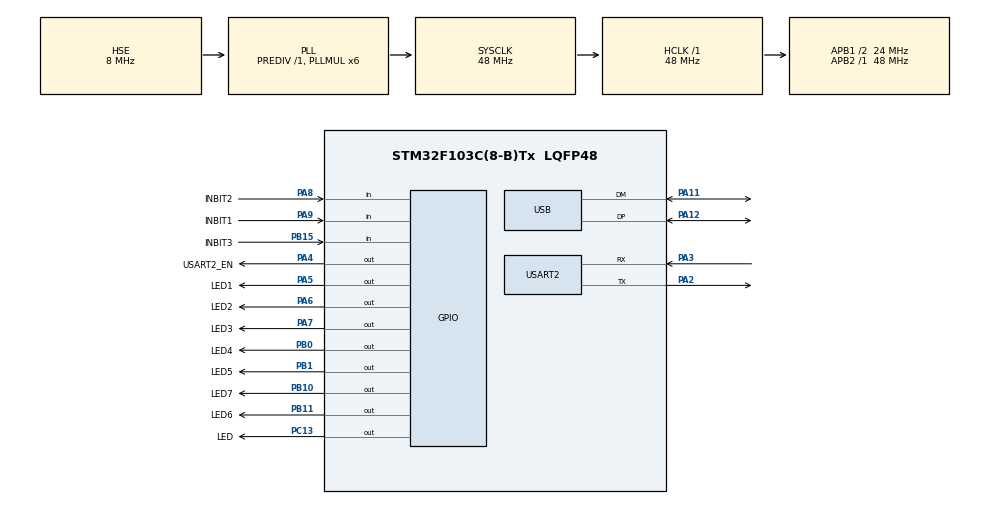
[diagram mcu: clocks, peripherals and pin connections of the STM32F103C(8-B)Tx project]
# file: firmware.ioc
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Mcu.Family=STM32F1
Mcu.Name=STM32F103C(8-B)Tx
Mcu.Package=LQFP48
NVIC.PriorityGroup=NVIC_PRIORITYGROUP_4
NVIC.USB_LP_CAN1_RX0_IRQn=true\:0\:0\:false\:false\:true\:false\:true\:true
PA11.Mode=Device
PA11.Signal=USB_DM
PA12.Mode=Device
PA12.Signal=USB_DP
PA13.Mode=Serial_Wire
PA13.Signal=SYS_JTMS-SWDIO
PA14.Mode=Serial_Wire
PA14.Signal=SYS_JTCK-SWCLK
PA2.Mode=Asynchronous
PA2.Signal=USART2_TX
PA3.Mode=Asynchronous
PA3.Signal=USART2_RX
PA4.GPIO_Label=USART2_EN
PA4.Signal=GPIO_Output
PA5.GPIO_Label=LED1
PA5.Signal=GPIO_Output
PA6.GPIO_Label=LED2
PA6.Signal=GPIO_Output
PA7.GPIO_Label=LED3
PA7.Signal=GPIO_Output
PA8.GPIO_Label=INBIT2
PA8.GPIO_PuPd=GPIO_PULLUP
PA8.Signal=GPIO_Input
PA9.GPIO_Label=INBIT1
PA9.GPIO_PuPd=GPIO_PULLUP
PA9.Signal=GPIO_Input
PB0.GPIO_Label=LED4
PB0.Signal=GPIO_Output
PB1.GPIO_Label=LED5
PB1.Signal=GPIO_Output
PB10.GPIO_Label=LED7
PB10.Signal=GPIO_Output
PB11.GPIO_Label=LED6
PB11.Signal=GPIO_Output
PB15.GPIO_Label=INBIT3
PB15.GPIO_PuPd=GPIO_PULLUP
PB15.Signal=GPIO_Input
PC13-TAMPER-RTC.GPIO_Label=LED
PC13-TAMPER-RTC.Signal=GPIO_Output
PD0-OSC_IN.Mode=HSE-External-Oscillator
PD0-OSC_IN.Signal=RCC_OSC_IN
PD1-OSC_OUT.Mode=HSE-External-Oscillator
PD1-OSC_OUT.Signal=RCC_OSC_OUT
ProjectManager.HeapSize=0x200
ProjectManager.StackSize=0x400
ProjectManager.TargetToolchain=STM32CubeIDE
RCC.AHBFreq_Value=48000000
RCC.APB1CLKDivider=RCC_HCLK_DIV2
RCC.APB1Freq_Value=24000000
RCC.APB1TimFreq_Value=48000000
RCC.APB2Freq_Value=48000000
RCC.APB2TimFreq_Value=48000000
RCC.HCLKFreq_Value=48000000
RCC.PLLMUL=RCC_PLL_MUL6
RCC.SYSCLKFreq_VALUE=48000000
RCC.SYSCLKSource=RCC_SYSCLKSOURCE_PLLCLK
RCC.USBFreq_Value=48000000
USART2.VirtualMode=VM_ASYNC
USB_DEVICE.CLASS_NAME_FS=CDC
USB_DEVICE.VirtualMode=Cdc
USB_DEVICE.VirtualModeFS=Cdc_FS
VP_TIM1_VS_ClockSourceINT.Mode=Internal
VP_USB_DEVICE_VS_USB_DEVICE_CDC_FS.Mode=CDC_FS
board=custom

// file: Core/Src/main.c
/* USER CODE BEGIN Header */
/**
  ******************************************************************************
  * @file           : main.c
  * @brief          : Main program body
  ******************************************************************************
  * @attention
  *
  * Copyright (c) 2026 STMicroelectronics.
  * All rights reserved.
  *
  * This software is licensed under terms that can be found in the LICENSE file
  * in the root directory of this software component.
  * If no LICENSE file comes with this software, it is provided AS-IS.
  *
  ******************************************************************************
  */
/* USER CODE END Header */
#include "main.h"
#include "usb_device.h"
#include "usbd_cdc_if.h"

TIM_HandleTypeDef htim1;

UART_HandleTypeDef huart2;

void SystemClock_Config(void);
static void MX_GPIO_Init(void);
static void MX_TIM1_Init(void);
static void MX_USART2_UART_Init(void);
/* USER CODE BEGIN PFP */
static void ApplyVixenChannels(const uint8_t *channels, uint16_t channel_count);

/* USER CODE END PFP */

int main(void)
{

  /* MCU Configuration--------------------------------------------------------*/

  /* Reset of all peripherals, Initializes the Flash interface and the Systick. */
  HAL_Init();

  /* Configure the system clock */
  SystemClock_Config();

  /* Initialize all configured peripherals */
  MX_GPIO_Init();
  MX_TIM1_Init();
  MX_USART2_UART_Init();
  MX_USB_DEVICE_Init();

  /* Infinite loop */
  /* USER CODE BEGIN WHILE */
  while (1)
  {
    uint8_t channels[VIXEN_MAX_CHANNELS];
    uint16_t channel_count = CDC_GetReceivedFrame(channels, VIXEN_MAX_CHANNELS);
    if (channel_count != 0U)
    {
      ApplyVixenChannels(channels, channel_count);
    }

    /* USER CODE END WHILE */

  }
}

void SystemClock_Config(void)
{
  RCC_OscInitTypeDef RCC_OscInitStruct = {0};
  RCC_ClkInitTypeDef RCC_ClkInitStruct = {0};
  RCC_PeriphCLKInitTypeDef PeriphClkInit = {0};

  /** Initializes the RCC Oscillators according to the specified parameters
  * in the RCC_OscInitTypeDef structure.
  */
  RCC_OscInitStruct.OscillatorType = RCC_OSCILLATORTYPE_HSE;
  RCC_OscInitStruct.HSEState = RCC_HSE_ON;
  RCC_OscInitStruct.HSEPredivValue = RCC_HSE_PREDIV_DIV1;
  RCC_OscInitStruct.HSIState = RCC_HSI_ON;
  RCC_OscInitStruct.PLL.PLLState = RCC_PLL_ON;
  RCC_OscInitStruct.PLL.PLLSource = RCC_PLLSOURCE_HSE;
  RCC_OscInitStruct.PLL.PLLMUL = RCC_PLL_MUL6;
  if (HAL_RCC_OscConfig(&RCC_OscInitStruct) != HAL_OK)
  {
    Error_Handler();
  }

  /** Initializes the CPU, AHB and APB buses clocks
  */
  RCC_ClkInitStruct.ClockType = RCC_CLOCKTYPE_HCLK|RCC_CLOCKTYPE_SYSCLK
                              |RCC_CLOCKTYPE_PCLK1|RCC_CLOCKTYPE_PCLK2;
  RCC_ClkInitStruct.SYSCLKSource = RCC_SYSCLKSOURCE_PLLCLK;
  RCC_ClkInitStruct.AHBCLKDivider = RCC_SYSCLK_DIV1;
  RCC_ClkInitStruct.APB1CLKDivider = RCC_HCLK_DIV2;
  RCC_ClkInitStruct.APB2CLKDivider = RCC_HCLK_DIV1;

  if (HAL_RCC_ClockConfig(&RCC_ClkInitStruct, FLASH_LATENCY_1) != HAL_OK)
  {
    Error_Handler();
  }
  PeriphClkInit.PeriphClockSelection = RCC_PERIPHCLK_USB;
  PeriphClkInit.UsbClockSelection = RCC_USBCLKSOURCE_PLL;
  if (HAL_RCCEx_PeriphCLKConfig(&PeriphClkInit) != HAL_OK)
  {
    Error_Handler();
  }
}

static void MX_TIM1_Init(void)
{

  TIM_ClockConfigTypeDef sClockSourceConfig = {0};
  TIM_MasterConfigTypeDef sMasterConfig = {0};

  htim1.Instance = TIM1;
  htim1.Init.Prescaler = 0;
  htim1.Init.CounterMode = TIM_COUNTERMODE_UP;
  htim1.Init.Period = 65535;
  htim1.Init.ClockDivision = TIM_CLOCKDIVISION_DIV1;
  htim1.Init.RepetitionCounter = 0;
  htim1.Init.AutoReloadPreload = TIM_AUTORELOAD_PRELOAD_DISABLE;
  if (HAL_TIM_Base_Init(&htim1) != HAL_OK)
  {
    Error_Handler();
  }
  sClockSourceConfig.ClockSource = TIM_CLOCKSOURCE_INTERNAL;
  if (HAL_TIM_ConfigClockSource(&htim1, &sClockSourceConfig) != HAL_OK)
  {
    Error_Handler();
  }
  sMasterConfig.MasterOutputTrigger = TIM_TRGO_RESET;
  sMasterConfig.MasterSlaveMode = TIM_MASTERSLAVEMODE_DISABLE;
  if (HAL_TIMEx_MasterConfigSynchronization(&htim1, &sMasterConfig) != HAL_OK)
  {
    Error_Handler();
  }

}

static void MX_USART2_UART_Init(void)
{

  huart2.Instance = USART2;
  huart2.Init.BaudRate = 115200;
  huart2.Init.WordLength = UART_WORDLENGTH_8B;
  huart2.Init.StopBits = UART_STOPBITS_1;
  huart2.Init.Parity = UART_PARITY_NONE;
  huart2.Init.Mode = UART_MODE_TX_RX;
  huart2.Init.HwFlowCtl = UART_HWCONTROL_NONE;
  huart2.Init.OverSampling = UART_OVERSAMPLING_16;
  if (HAL_UART_Init(&huart2) != HAL_OK)
  {
    Error_Handler();
  }

}

static void MX_GPIO_Init(void)
{
  GPIO_InitTypeDef GPIO_InitStruct = {0};

  /* GPIO Ports Clock Enable */
  __HAL_RCC_GPIOC_CLK_ENABLE();
  __HAL_RCC_GPIOD_CLK_ENABLE();
  __HAL_RCC_GPIOA_CLK_ENABLE();
  __HAL_RCC_GPIOB_CLK_ENABLE();

  /*Configure GPIO pin Output Level */
  HAL_GPIO_WritePin(LED_GPIO_Port, LED_Pin, GPIO_PIN_RESET);

  /*Configure GPIO pin Output Level */
  HAL_GPIO_WritePin(GPIOA, USART2_EN_Pin|LED1_Pin|LED2_Pin|LED3_Pin, GPIO_PIN_RESET);

  /*Configure GPIO pin Output Level */
  HAL_GPIO_WritePin(GPIOB, LED4_Pin|LED5_Pin|LED7_Pin|LED6_Pin, GPIO_PIN_RESET);

  /*Configure GPIO pin : LED_Pin */
  GPIO_InitStruct.Pin = LED_Pin;
  GPIO_InitStruct.Mode = GPIO_MODE_OUTPUT_PP;
  GPIO_InitStruct.Pull = GPIO_NOPULL;
  GPIO_InitStruct.Speed = GPIO_SPEED_FREQ_LOW;
  HAL_GPIO_Init(LED_GPIO_Port, &GPIO_InitStruct);

  /*Configure GPIO pins : USART2_EN_Pin LED1_Pin LED2_Pin LED3_Pin */
  GPIO_InitStruct.Pin = USART2_EN_Pin|LED1_Pin|LED2_Pin|LED3_Pin;
  GPIO_InitStruct.Mode = GPIO_MODE_OUTPUT_PP;
  GPIO_InitStruct.Pull = GPIO_NOPULL;
  GPIO_InitStruct.Speed = GPIO_SPEED_FREQ_LOW;
  HAL_GPIO_Init(GPIOA, &GPIO_InitStruct);

  /*Configure GPIO pins : LED4_Pin LED5_Pin LED7_Pin LED6_Pin */
  GPIO_InitStruct.Pin = LED4_Pin|LED5_Pin|LED7_Pin|LED6_Pin;
  GPIO_InitStruct.Mode = GPIO_MODE_OUTPUT_PP;
  GPIO_InitStruct.Pull = GPIO_NOPULL;
  GPIO_InitStruct.Speed = GPIO_SPEED_FREQ_LOW;
  HAL_GPIO_Init(GPIOB, &GPIO_InitStruct);

  /*Configure GPIO pin : INBIT3_Pin */
  GPIO_InitStruct.Pin = INBIT3_Pin;
  GPIO_InitStruct.Mode = GPIO_MODE_INPUT;
  GPIO_InitStruct.Pull = GPIO_PULLUP;
  HAL_GPIO_Init(INBIT3_GPIO_Port, &GPIO_InitStruct);

  /*Configure GPIO pins : INBIT2_Pin INBIT1_Pin */
  GPIO_InitStruct.Pin = INBIT2_Pin|INBIT1_Pin;
  GPIO_InitStruct.Mode = GPIO_MODE_INPUT;
  GPIO_InitStruct.Pull = GPIO_PULLUP;
  HAL_GPIO_Init(GPIOA, &GPIO_InitStruct);

}

/* USER CODE BEGIN 4 */
static void ApplyVixenChannels(const uint8_t *channels, uint16_t channel_count)
{
  HAL_GPIO_WritePin(LED1_GPIO_Port, LED1_Pin, (channel_count > 0U) && (channels[0] != 0U) ? GPIO_PIN_SET : GPIO_PIN_RESET);
  HAL_GPIO_WritePin(LED2_GPIO_Port, LED2_Pin, (channel_count > 1U) && (channels[1] != 0U) ? GPIO_PIN_SET : GPIO_PIN_RESET);
  HAL_GPIO_WritePin(LED3_GPIO_Port, LED3_Pin, (channel_count > 2U) && (channels[2] != 0U) ? GPIO_PIN_SET : GPIO_PIN_RESET);
  HAL_GPIO_WritePin(LED4_GPIO_Port, LED4_Pin, (channel_count > 3U) && (channels[3] != 0U) ? GPIO_PIN_SET : GPIO_PIN_RESET);
  HAL_GPIO_WritePin(LED5_GPIO_Port, LED5_Pin, (channel_count > 4U) && (channels[4] != 0U) ? GPIO_PIN_SET : GPIO_PIN_RESET);
  HAL_GPIO_WritePin(LED6_GPIO_Port, LED6_Pin, (channel_count > 5U) && (channels[5] != 0U) ? GPIO_PIN_SET : GPIO_PIN_RESET);
  HAL_GPIO_WritePin(LED7_GPIO_Port, LED7_Pin, (channel_count > 6U) && (channels[6] != 0U) ? GPIO_PIN_SET : GPIO_PIN_RESET);
  HAL_GPIO_WritePin(LED_GPIO_Port, LED_Pin, (channel_count > 7U) && (channels[7] != 0U) ? GPIO_PIN_SET : GPIO_PIN_RESET);
}

/* USER CODE END 4 */

void Error_Handler(void)
{
  __disable_irq();
  while (1)
  {
  }
}
